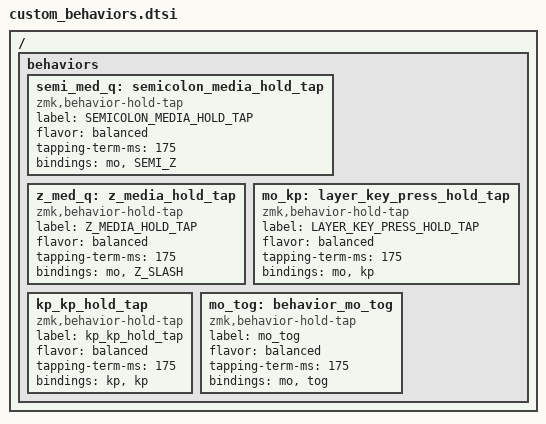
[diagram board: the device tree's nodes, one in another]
#include <dt-bindings/zmk/keys.h>
#include "dvorak_qwerty.dtsi"

/ {
    behaviors {
        semi_med_q: semicolon_media_hold_tap {
            compatible = "zmk,behavior-hold-tap";
            label = "SEMICOLON_MEDIA_HOLD_TAP";
            #binding-cells = <2>;
            flavor = "balanced";
            tapping-term-ms = <175>;
            bindings = <&mo>, <&SEMI_Z>;
        };
        z_med_q: z_media_hold_tap {
            compatible = "zmk,behavior-hold-tap";
            label = "Z_MEDIA_HOLD_TAP";
            #binding-cells = <2>;
            flavor = "balanced";
            tapping-term-ms = <175>;
            bindings = <&mo>, <&Z_SLASH>;
        };
        mo_kp: layer_key_press_hold_tap {
            compatible = "zmk,behavior-hold-tap";
            label = "LAYER_KEY_PRESS_HOLD_TAP";
            #binding-cells = <2>;
            flavor = "balanced";
            tapping-term-ms = <175>;
            bindings = <&mo>, <&kp>;
        };
        kp_kp_hold_tap: kp_kp_hold_tap {
            compatible = "zmk,behavior-hold-tap";
            label = "kp_kp_hold_tap";
            #binding-cells = <2>;
            flavor = "balanced";
            tapping-term-ms = <175>;
            bindings = <&kp>, <&kp>;
        };
        mo_tog: behavior_mo_tog {
            compatible = "zmk,behavior-hold-tap";
            label = "mo_tog";
            #binding-cells = <2>;
            flavor = "balanced";
            tapping-term-ms = <175>;
            bindings = <&mo>, <&tog>;
        };
    };
};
